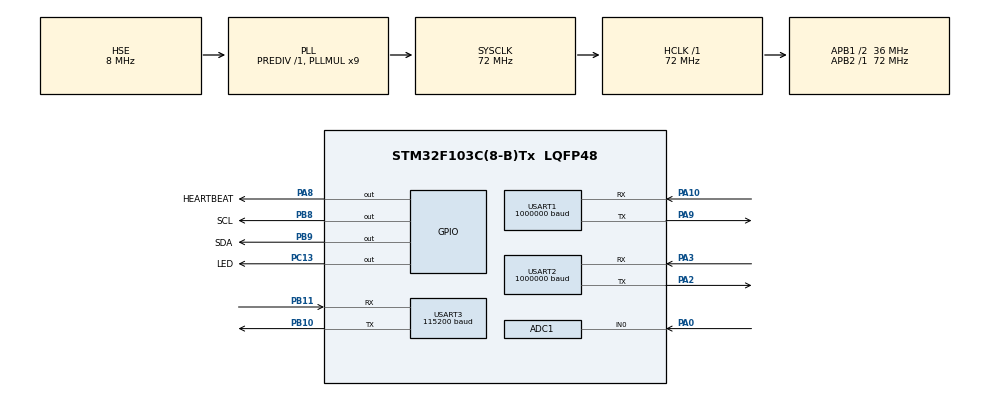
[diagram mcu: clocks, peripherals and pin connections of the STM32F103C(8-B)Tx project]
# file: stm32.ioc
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ADC1.Channel-0\#ChannelRegularConversion=ADC_CHANNEL_0
ADC1.ContinuousConvMode=ENABLE
ADC1.NbrOfConversion=1
ADC1.NbrOfConversionFlag=1
ADC1.Rank-0\#ChannelRegularConversion=1
ADC1.SamplingTime-0\#ChannelRegularConversion=ADC_SAMPLETIME_239CYCLES_5
ADC1.master=1
Dma.ADC1.0.Direction=DMA_PERIPH_TO_MEMORY
Dma.ADC1.0.Instance=DMA1_Channel1
Dma.ADC1.0.MemDataAlignment=DMA_MDATAALIGN_HALFWORD
Dma.ADC1.0.MemInc=DMA_MINC_ENABLE
Dma.ADC1.0.Mode=DMA_CIRCULAR
Dma.ADC1.0.PeriphDataAlignment=DMA_PDATAALIGN_HALFWORD
Dma.ADC1.0.PeriphInc=DMA_PINC_DISABLE
Dma.ADC1.0.Priority=DMA_PRIORITY_LOW
Dma.Request0=ADC1
Dma.Request1=USART2_RX
Dma.USART2_RX.1.Direction=DMA_PERIPH_TO_MEMORY
Dma.USART2_RX.1.Instance=DMA1_Channel6
Dma.USART2_RX.1.MemDataAlignment=DMA_MDATAALIGN_BYTE
Dma.USART2_RX.1.MemInc=DMA_MINC_ENABLE
Dma.USART2_RX.1.Mode=DMA_CIRCULAR
Dma.USART2_RX.1.PeriphDataAlignment=DMA_PDATAALIGN_BYTE
Dma.USART2_RX.1.PeriphInc=DMA_PINC_DISABLE
Dma.USART2_RX.1.Priority=DMA_PRIORITY_LOW
Mcu.Family=STM32F1
Mcu.Name=STM32F103C(8-B)Tx
Mcu.Package=LQFP48
NVIC.ADC1_2_IRQn=true\:0\:0\:false\:false\:true\:true\:true
NVIC.DMA1_Channel1_IRQn=true\:5\:0\:true\:false\:true\:false\:true
NVIC.DMA1_Channel6_IRQn=true\:6\:0\:true\:false\:true\:false\:true
NVIC.PriorityGroup=NVIC_PRIORITYGROUP_4
NVIC.USART1_IRQn=true\:7\:0\:true\:false\:true\:true\:true
NVIC.USART2_IRQn=true\:6\:0\:true\:false\:true\:true\:true
NVIC.USART3_IRQn=true\:8\:0\:true\:false\:true\:true\:true
PA0-WKUP.Signal=ADCx_IN0
PA10.Mode=Asynchronous
PA10.Signal=USART1_RX
PA13.Mode=Serial_Wire
PA13.Signal=SYS_JTMS-SWDIO
PA14.Mode=Serial_Wire
PA14.Signal=SYS_JTCK-SWCLK
PA2.Mode=Asynchronous
PA2.Signal=USART2_TX
PA3.Mode=Asynchronous
PA3.Signal=USART2_RX
PA8.GPIO_Label=HEARTBEAT
PA8.Signal=GPIO_Output
PA9.Mode=Asynchronous
PA9.Signal=USART1_TX
PB10.Mode=Asynchronous
PB10.Signal=USART3_TX
PB11.Mode=Asynchronous
PB11.Signal=USART3_RX
PB8.GPIO_Label=SCL
PB8.GPIO_ModeDefaultOutputPP=GPIO_MODE_OUTPUT_OD
PB8.GPIO_PuPd=GPIO_NOPULL
PB8.GPIO_Speed=GPIO_SPEED_FREQ_HIGH
PB8.Signal=GPIO_Output
PB9.GPIO_Label=SDA
PB9.GPIO_ModeDefaultOutputPP=GPIO_MODE_OUTPUT_OD
PB9.GPIO_PuPd=GPIO_NOPULL
PB9.GPIO_Speed=GPIO_SPEED_FREQ_HIGH
PB9.Signal=GPIO_Output
PC13-TAMPER-RTC.GPIO_Label=LED
PC13-TAMPER-RTC.PinState=GPIO_PIN_SET
PC13-TAMPER-RTC.Signal=GPIO_Output
PD0-OSC_IN.Mode=HSE-External-Oscillator
PD0-OSC_IN.Signal=RCC_OSC_IN
PD1-OSC_OUT.Mode=HSE-External-Oscillator
PD1-OSC_OUT.Signal=RCC_OSC_OUT
ProjectManager.HeapSize=0x00
ProjectManager.StackSize=0x400
ProjectManager.TargetToolchain=MDK-ARM V5.32
RCC.ADCPresc=RCC_ADCPCLK2_DIV6
RCC.AHBFreq_Value=72000000
RCC.APB1CLKDivider=RCC_HCLK_DIV2
RCC.APB1Freq_Value=36000000
RCC.APB1TimFreq_Value=72000000
RCC.APB2Freq_Value=72000000
RCC.APB2TimFreq_Value=72000000
RCC.HCLKFreq_Value=72000000
RCC.PLLMUL=RCC_PLL_MUL9
RCC.PLLSourceVirtual=RCC_PLLSOURCE_HSE
RCC.SYSCLKFreq_VALUE=72000000
RCC.SYSCLKSource=RCC_SYSCLKSOURCE_PLLCLK
RCC.USBFreq_Value=72000000
SH.ADCx_IN0.0=ADC1_IN0,IN0
USART1.BaudRate=1000000
USART1.VirtualMode=VM_ASYNC
USART2.BaudRate=1000000
USART2.VirtualMode=VM_ASYNC
USART3.BaudRate=115200
USART3.VirtualMode=VM_ASYNC
board=custom

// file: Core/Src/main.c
/* USER CODE BEGIN Header */
/**
  ******************************************************************************
  * @file           : main.c
  * @brief          : Main program body
  ******************************************************************************
  * @attention
  *
  * Copyright (c) 2026 STMicroelectronics.
  * All rights reserved.
  *
  * This software is licensed under terms that can be found in the LICENSE file
  * in the root directory of this software component.
  * If no LICENSE file comes with this software, it is provided AS-IS.
  *
  ******************************************************************************
  */
/* USER CODE END Header */
#include "main.h"

/* USER CODE BEGIN Includes */
#include "rlcat_config.h"
#include "app_main.h"
#include "bsp_gpio.h"
/* USER CODE END Includes */

ADC_HandleTypeDef hadc1;
DMA_HandleTypeDef hdma_adc1;

UART_HandleTypeDef huart1;
UART_HandleTypeDef huart2;
UART_HandleTypeDef huart3;
DMA_HandleTypeDef hdma_usart2_rx;

void SystemClock_Config(void);
static void MX_GPIO_Init(void);
static void MX_DMA_Init(void);
static void MX_ADC1_Init(void);
static void MX_USART1_UART_Init(void);
static void MX_USART2_UART_Init(void);
static void MX_USART3_UART_Init(void);

int main(void)
{

  /* MCU Configuration--------------------------------------------------------*/

  /* Reset of all peripherals, Initializes the Flash interface and the Systick. */
  HAL_Init();

  /* Configure the system clock */
  SystemClock_Config();

  /* Initialize all configured peripherals */
  MX_GPIO_Init();
  MX_DMA_Init();
  MX_ADC1_Init();
  MX_USART1_UART_Init();
  MX_USART2_UART_Init();
  MX_USART3_UART_Init();
  /* USER CODE BEGIN 2 */
  /* ⚠️ 全部应用层初始化都在这里�?
   *    app_init() 内部按序�? bsp_tick �? bsp_gpio �? bsp_uart �? bsp_softi2c
   *    �? 上电自检 �? shell。顺序不能乱（后面都依赖 bsp_tick）�??
   *    阶段说明�? docs/33-firmware-plan.md §9�? */
  app_init();
  /* USER CODE END 2 */

  /* Infinite loop */
  while (1)
  {

    /* USER CODE BEGIN 3 */
    /* �? 高频任务：搬 DMA 缓冲、解�? shell/协议、心跳与状�?�灯 */
    app_poll();

    /* �? 100 Hz 控制�? */
    if (app_should_run_cycle())
    {
      app_cycle_100hz();
    }

    /* �? 低频任务（心跳已�? app_poll 里推进；此处留扩展点�? */
    app_housekeeping();
  }
  /* USER CODE END 3 */
}

void SystemClock_Config(void)
{
  RCC_OscInitTypeDef RCC_OscInitStruct = {0};
  RCC_ClkInitTypeDef RCC_ClkInitStruct = {0};
  RCC_PeriphCLKInitTypeDef PeriphClkInit = {0};

  /** Initializes the RCC Oscillators according to the specified parameters
  * in the RCC_OscInitTypeDef structure.
  */
  RCC_OscInitStruct.OscillatorType = RCC_OSCILLATORTYPE_HSE;
  RCC_OscInitStruct.HSEState = RCC_HSE_ON;
  RCC_OscInitStruct.HSEPredivValue = RCC_HSE_PREDIV_DIV1;
  RCC_OscInitStruct.HSIState = RCC_HSI_ON;
  RCC_OscInitStruct.PLL.PLLState = RCC_PLL_ON;
  RCC_OscInitStruct.PLL.PLLSource = RCC_PLLSOURCE_HSE;
  RCC_OscInitStruct.PLL.PLLMUL = RCC_PLL_MUL9;
  if (HAL_RCC_OscConfig(&RCC_OscInitStruct) != HAL_OK)
  {
    Error_Handler();
  }
  /** Initializes the CPU, AHB and APB buses clocks
  */
  RCC_ClkInitStruct.ClockType = RCC_CLOCKTYPE_HCLK|RCC_CLOCKTYPE_SYSCLK
                              |RCC_CLOCKTYPE_PCLK1|RCC_CLOCKTYPE_PCLK2;
  RCC_ClkInitStruct.SYSCLKSource = RCC_SYSCLKSOURCE_PLLCLK;
  RCC_ClkInitStruct.AHBCLKDivider = RCC_SYSCLK_DIV1;
  RCC_ClkInitStruct.APB1CLKDivider = RCC_HCLK_DIV2;
  RCC_ClkInitStruct.APB2CLKDivider = RCC_HCLK_DIV1;

  if (HAL_RCC_ClockConfig(&RCC_ClkInitStruct, FLASH_LATENCY_2) != HAL_OK)
  {
    Error_Handler();
  }
  PeriphClkInit.PeriphClockSelection = RCC_PERIPHCLK_ADC;
  PeriphClkInit.AdcClockSelection = RCC_ADCPCLK2_DIV6;
  if (HAL_RCCEx_PeriphCLKConfig(&PeriphClkInit) != HAL_OK)
  {
    Error_Handler();
  }
}

static void MX_ADC1_Init(void)
{

  ADC_ChannelConfTypeDef sConfig = {0};

  /** Common config
  */
  hadc1.Instance = ADC1;
  hadc1.Init.ScanConvMode = ADC_SCAN_DISABLE;
  hadc1.Init.ContinuousConvMode = ENABLE;
  hadc1.Init.DiscontinuousConvMode = DISABLE;
  hadc1.Init.ExternalTrigConv = ADC_SOFTWARE_START;
  hadc1.Init.DataAlign = ADC_DATAALIGN_RIGHT;
  hadc1.Init.NbrOfConversion = 1;
  if (HAL_ADC_Init(&hadc1) != HAL_OK)
  {
    Error_Handler();
  }
  /** Configure Regular Channel
  */
  sConfig.Channel = ADC_CHANNEL_0;
  sConfig.Rank = ADC_REGULAR_RANK_1;
  sConfig.SamplingTime = ADC_SAMPLETIME_239CYCLES_5;
  if (HAL_ADC_ConfigChannel(&hadc1, &sConfig) != HAL_OK)
  {
    Error_Handler();
  }

}

static void MX_USART1_UART_Init(void)
{

  huart1.Instance = USART1;
  /* ⭐ 2026-10-18：USART1 ↔ 树莓派从 1 Mbps 降到 500 kbps。
   *
   *  ⚠️ 原因（实测）：`R` 的链路错误分解显示
   *        link_rx_frames   = 285   完整帧
   *        link_rx_timeouts = 349   ⚠️ 半帧超时（收一半就断）
   *        link_crc_errors  = 10
   *     半帧数比完整帧还多 ⇒ **字节在传输中途丢失**，
   *     是典型的 1 Mbps 信号完整性问题（共地/线长/无屏蔽/时钟偏差）。
   *
   *  ⭐ 带宽核算（500 kbps = 50 kB/s）：
   *        Pi→32  CMD_JOINT  38 B × 100 Hz =  3.8 kB/s
   *        32→Pi  TEL_FAST  103 B × 100 Hz = 10.3 kB/s
   *               TEL_STATUS 47 B ×  10 Hz =  0.5 kB/s
   *        合计 ≈ 14.6 kB/s = 29% 占用，余量充足。
   *
   *  ⚠️ 两个方向的分频都是整数（72 MHz / 500 kHz = 144；
   *     树莓派 PL011 48 MHz / 500 kHz = 96），没有累积误差。
   *  ⚠️ 树莓派侧必须同步改 config.py 的 SERIAL_BAUD。
   *  ⚠️ USART2（舵机板）保持 1 Mbps —— 舵机出厂就是这个速率。 */
  huart1.Init.BaudRate = 500000;
  huart1.Init.WordLength = UART_WORDLENGTH_8B;
  huart1.Init.StopBits = UART_STOPBITS_1;
  huart1.Init.Parity = UART_PARITY_NONE;
  huart1.Init.Mode = UART_MODE_TX_RX;
  huart1.Init.HwFlowCtl = UART_HWCONTROL_NONE;
  huart1.Init.OverSampling = UART_OVERSAMPLING_16;
  if (HAL_UART_Init(&huart1) != HAL_OK)
  {
    Error_Handler();
  }

}

static void MX_USART2_UART_Init(void)
{

  huart2.Instance = USART2;
  huart2.Init.BaudRate = 1000000;
  huart2.Init.WordLength = UART_WORDLENGTH_8B;
  huart2.Init.StopBits = UART_STOPBITS_1;
  huart2.Init.Parity = UART_PARITY_NONE;
  huart2.Init.Mode = UART_MODE_TX_RX;
  huart2.Init.HwFlowCtl = UART_HWCONTROL_NONE;
  huart2.Init.OverSampling = UART_OVERSAMPLING_16;
  if (HAL_UART_Init(&huart2) != HAL_OK)
  {
    Error_Handler();
  }

}

static void MX_USART3_UART_Init(void)
{

  huart3.Instance = USART3;
  huart3.Init.BaudRate = 115200;
  huart3.Init.WordLength = UART_WORDLENGTH_8B;
  huart3.Init.StopBits = UART_STOPBITS_1;
  huart3.Init.Parity = UART_PARITY_NONE;
  huart3.Init.Mode = UART_MODE_TX_RX;
  huart3.Init.HwFlowCtl = UART_HWCONTROL_NONE;
  huart3.Init.OverSampling = UART_OVERSAMPLING_16;
  if (HAL_UART_Init(&huart3) != HAL_OK)
  {
    Error_Handler();
  }

}

static void MX_DMA_Init(void)
{

  /* DMA controller clock enable */
  __HAL_RCC_DMA1_CLK_ENABLE();

  /* DMA interrupt init */
  /* DMA1_Channel1_IRQn interrupt configuration */
  HAL_NVIC_SetPriority(DMA1_Channel1_IRQn, 5, 0);
  HAL_NVIC_EnableIRQ(DMA1_Channel1_IRQn);
  /* DMA1_Channel6_IRQn interrupt configuration */
  HAL_NVIC_SetPriority(DMA1_Channel6_IRQn, 6, 0);
  HAL_NVIC_EnableIRQ(DMA1_Channel6_IRQn);

}

static void MX_GPIO_Init(void)
{
  GPIO_InitTypeDef GPIO_InitStruct = {0};

  /* GPIO Ports Clock Enable */
  __HAL_RCC_GPIOC_CLK_ENABLE();
  __HAL_RCC_GPIOD_CLK_ENABLE();
  __HAL_RCC_GPIOA_CLK_ENABLE();
  __HAL_RCC_GPIOB_CLK_ENABLE();

  /*Configure GPIO pin Output Level */
  HAL_GPIO_WritePin(LED_GPIO_Port, LED_Pin, GPIO_PIN_SET);

  /*Configure GPIO pin Output Level */
  HAL_GPIO_WritePin(HEARTBEAT_GPIO_Port, HEARTBEAT_Pin, GPIO_PIN_RESET);

  /*Configure GPIO pin Output Level */
  HAL_GPIO_WritePin(GPIOB, SCL_Pin|SDA_Pin, GPIO_PIN_RESET);

  /*Configure GPIO pin : LED_Pin */
  GPIO_InitStruct.Pin = LED_Pin;
  GPIO_InitStruct.Mode = GPIO_MODE_OUTPUT_PP;
  GPIO_InitStruct.Pull = GPIO_NOPULL;
  GPIO_InitStruct.Speed = GPIO_SPEED_FREQ_LOW;
  HAL_GPIO_Init(LED_GPIO_Port, &GPIO_InitStruct);

  /*Configure GPIO pin : HEARTBEAT_Pin */
  GPIO_InitStruct.Pin = HEARTBEAT_Pin;
  GPIO_InitStruct.Mode = GPIO_MODE_OUTPUT_PP;
  GPIO_InitStruct.Pull = GPIO_NOPULL;
  GPIO_InitStruct.Speed = GPIO_SPEED_FREQ_LOW;
  HAL_GPIO_Init(HEARTBEAT_GPIO_Port, &GPIO_InitStruct);

  /*Configure GPIO pins : SCL_Pin SDA_Pin */
  GPIO_InitStruct.Pin = SCL_Pin|SDA_Pin;
  GPIO_InitStruct.Mode = GPIO_MODE_OUTPUT_OD;
  GPIO_InitStruct.Pull = GPIO_NOPULL;
  GPIO_InitStruct.Speed = GPIO_SPEED_FREQ_HIGH;
  HAL_GPIO_Init(GPIOB, &GPIO_InitStruct);

}

void Error_Handler(void)
{
  /* USER CODE BEGIN Error_Handler_Debug */
  /* ⚠️ 不再�?"关中断死循环"：那样无法区�?
   *      "启动失败"（LED 快闪）与"程序根本没跑"（LED 不亮）�??
   *    bsp_fatal_error() 会让 PB0 �? 10 Hz 快闪后死循环�? */
  bsp_fatal_error();
  /* USER CODE END Error_Handler_Debug */
}
